# cyt6bj register map
Vendor: Cypress Semiconductor; Series: cyt6bj; File version: 1.0
CPU: CM7 r0p1, little endian, MPU, FPU, VTOR, 3 interrupt priority bits
Registers are 32-bit, read-write, reset 0x0 unless marked. A register's access mark holds for its fields unless they carry their own. Offsets are from the block's base; [hi:lo] are bit positions; {n}, {i} and the like mark numbered series; 'fields as' and 'values as' point back to an identical list; <NAME> marks a mode.

## CPUSS — CPU subsystem (CPUSS)
Base 0x40200000
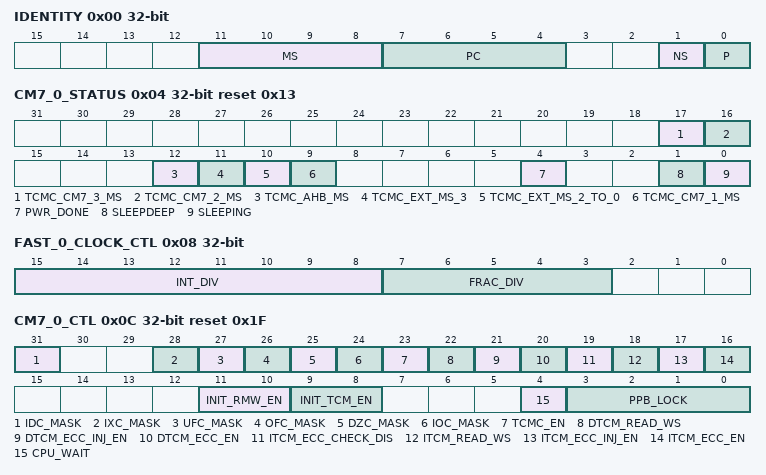
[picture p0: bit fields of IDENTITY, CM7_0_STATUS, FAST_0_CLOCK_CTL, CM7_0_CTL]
0x00 IDENTITY ro reset not defined
  [11:8] MS — This field specifies the bus master identifier of the transfer that reads the register.
  [7:4] PC — This field specifies the protection context of the transfer that reads the register.
  [1] NS — This field specifies the security setting ('0': secure mode; '1': non-secure mode) of the transfer that reads the register.
  [0] P — This field specifies the privileged setting ('0': user mode; '1': privileged mode) of the transfer that reads the register.
0x04 CM7_0_STATUS ro reset 0x13
  [17] TCMC_CM7_3_MS — Outstanding transactions from CM7 3. '0': There are no outstanding transactions to the CM7 I/D-TCM slave port (AHBS) from CM7 3. '1': There are outstanding transactions to the CM7 I/D-TCM slave port (AHBS) from CM7 3. Do not switch the CM7 power off.
  [16] TCMC_CM7_2_MS — Outstanding transactions from CM7 2. '0': There are no outstanding transactions to the CM7 I/D-TCM slave port (AHBS) from CM7 2. '1': There are outstanding transactions to the CM7 I/D-TCM slave port (AHBS) from CM7 2. Do not switch the CM7 power off.
  [12] TCMC_AHB_MS — Ongoing AHB transaction. '0': There is no ongoing transaction to the CM7 I/D-TCM slave port (AHBS) from an AHB master. '1': There is an ongoing transaction to the CM7 I/D-TCM slave port (AHBS) from an AHB master. Do not switch the CM7 power off.
  [11] TCMC_EXT_MS_3 — Outstanding transactions from external AXI master 3. '0': There are no outstanding transactions to the CM7 I/D-TCM slave port (AHBS) from external AXI master 3. '1': There are outstanding transactions to the CM7 I/D-TCM slave port (AHBS) from external AXI master 3. Do not switch the CM7 power off.
  [10] TCMC_EXT_MS_2_TO_0 — Outstanding transactions from external AXI masters 2 to 0. '0': There are no outstanding transactions to the CM7 I/D-TCM slave port (AHBS) from external AXI masters 2 to 0. '1': There are outstanding transactions to the CM7 I/D-TCM slave port (AHBS) from external AXI masters 2 to 0. Do not switch the CM7 power off.
  [9] TCMC_CM7_1_MS — Outstanding transactions from CM7 1. '0': There are no outstanding transactions to the CM7 I/D-TCM slave port (AHBS) from CM7 1. '1': There are outstanding transactions to the CM7 I/D-TCM slave port (AHBS) from CM7 1. Do not switch the CM7 power off.
  [4] PWR_DONE — After a PWR_MODE change this flag indicates if the new power mode has taken effect or not. Note: this flag can also change as a result of a change in debug power up req
  [1] SLEEPDEEP — Specifies if the CPU is in Sleep or DeepSleep power mode. See SLEEPING field.
  [0] SLEEPING — Specifies if the CPU is in Active, Sleep or DeepSleep power mode: - Active power mode: SLEEPING is '0'. - Sleep power mode: SLEEPING is '1' and SLEEPDEEP is '0'. - DeepSleep power mode: SLEEPING is '1' and SLEEPDEEP is '1'.
0x08 FAST_0_CLOCK_CTL — Fast 0 clock control
  [15:8] INT_DIV — Integer division by (1+INT_DIV). Allows for integer divisions in the range [1, 256] (INT_DIV is in the range [0, 255]).
  [7:3] FRAC_DIV — Fractional division by (FRAC_DIV/32). Allows for fractional divisions in the range [0, 31/32]. Note that fractional division results in clock jitter as some clock periods may be 1 'clk_hf<x>' cycle longer than other clock periods.
0x0C CM7_0_CTL reset 0x1F — CM7 0 control
  [31] IDC_MASK — CPU FPU exception mask for the CPU's FPCSR.IDC 'input denormalized' exception condition: '0': The CPU's exception condition does NOT activate the CPU's floating point interrupt. '1': the CPU's exception condition activates the CPU's floating point interrupt. Note: if the CPU FPCSR.FZ field is set to '1', denormalized inputs are 'flushed to zero'. Dependent on the FPU algorithm, this may or may not occur frequently. To prevent frequent CPU FPU interrupts as a result of denormalized inputs, this field may be set to '0'.
  [28] IXC_MASK — CPU FPU exception mask for the CPU's FPCSR.IXC 'inexact' exception condition: '0': The CPU's exception condition does NOT activate the CPU's floating point interrupt. '1': the CPU's exception condition activates the CPU's floating point interrupt. Note: the 'inexact' condition is set as a result of rounding. Rounding may occur frequently and is typically not an error condition. To prevent frequent CPU FPU interrupts as a result of rounding, this field is typically set to '0'.
  [27] UFC_MASK — CPU FPU exception mask for the CPU's FPCSR.UFC 'underflow' exception condition: '0': The CPU's exception condition does NOT activate the CPU's floating point interrupt. '1': the CPU's exception condition activates the CPU's floating point interrupt.
  [26] OFC_MASK — CPU FPU exception mask for the CPU's FPCSR.OFC 'overflow' exception condition: '0': The CPU's exception condition does NOT activate the CPU's floating point interrupt. '1': the CPU's exception condition activates the CPU's floating point interrupt.
  [25] DZC_MASK — CPU FPU exception mask for the CPU's FPCSR.DZC 'divide by zero' exception condition: '0': The CPU's exception condition does NOT activate the CPU's floating point interrupt. '1': the CPU's exception condition activates the CPU's floating point interrupt.
  [24] IOC_MASK — CPU floating point unit (FPU) exception mask for the CPU's FPCSR.IOC 'invalid operation' exception condition: '0': The CPU's exception condition does NOT activate the CPU's floating point interrupt. '1': the CPU's exception condition activates the CPU's floating point interrupt. Note: the ARM architecture does NOT support FPU exceptions; i.e. there is no precise FPU exception handler. Instead, FPU conditions are captured in the CPU's FPCSR register and the conditions are provided as CPU interface signals. The interface signals are 'masked' with the fields a provide by this register (CM7_0_CTL). The 'masked' signals are reduced/OR-ed into a single CPU floating point interrupt signal. The associated CPU interrupt handler allows for imprecise handling of FPU exception conditions. Note: the CPU's FPCSR exception conditions are 'sticky'. Typically, the CPU FPU interrupt handler will clear the exception condition(s) to '0'. Note: by default, the FPU exception masks are '0'. Therefore, FPU exception conditions will NOT activate the CPU's floating point interrupt.
  [23] TCMC_EN — CM7 TCMC access control: '0': Disable access to the CM7 I/D-TCM slave port (AHBS). Access attempts will get a bus error response. '1': Enable access to the CM7 I/D-TCM slave port (AHBS). Before switching the CM7 power off, set this field to 0, and confirm that there are no outstanding AXI transactions and no ongoing AHB transactions to the CM7 TCMs, by checking that bits TCMC_* in CM7_x_STATUS are '0'.
  [22] DTCM_READ_WS — DTCM read wait states (writes have no wait states). '0': 0 wait states. '1': 1 wait state.
  [21] DTCM_ECC_INJ_EN — DTCM ECC error injection enable: '0': Disabled. '1': Enabled.
  [20] DTCM_ECC_EN — DTCM ECC enable: '0': Disabled. '1': Enabled.
  [19] ITCM_ECC_CHECK_DIS — Disable ECC checking and thus fault reports. This also disables ECC correction (required to enable initialization). Intended usage is initialization. This bit is ignored when TCM_ECC_EN=0.
  [18] ITCM_READ_WS — ITCM read wait states (writes have no wait states). '0': 0 wait states. '1': 1 wait state.
  [17] ITCM_ECC_INJ_EN — ITCM ECC error injection enable: '0': Disabled. '1': Enabled.
  [16] ITCM_ECC_EN — ITCM ECC enable: '0': Disabled. '1': Enabled.
  [11:10] INIT_RMW_EN — TCM read-modify-write enable initialization after reset: Bit 0: ITCM. '0': disabled; '1': enabled. Bit 1: DTCM. '0': disabled; '1': enabled. Note: When TCM ECC is enabled, the read-modify-write functionality should be enabled. This prevents partial (sub-word) writes to the TCM.
  [9:8] INIT_TCM_EN — TCM enable initialization after reset: Bit 0: ITCM. '0': disabled; '1': enabled. Bit 1: DTCM. '0': disabled; '1': enabled.
  [4] CPU_WAIT — When this signal is '1' out of reset, it forces the CPU into a quiescent state that delays its boot-up sequence and instruction execution until this signal is driven '0'. This allows the TCMs to be loaded by the system before the CPU performs any TCM accesses. The CPU AHBS interface functions while CPU_WAIT is '1' and services transactions initiated by the system (e.g. DMA controller) to load the TCMs.
  [3:0] PPB_LOCK — Write disable for specific CPU registers: Bit 0: ITCMR register. '0': enabled; '1': disabled. Bit 1: DTCMR register. '0': enabled; '1': disabled. Bit 2: AHBPCR register. '0': enabled; '1': disabled. Bit 3: VTOR register. '0': enabled; '1': disabled.
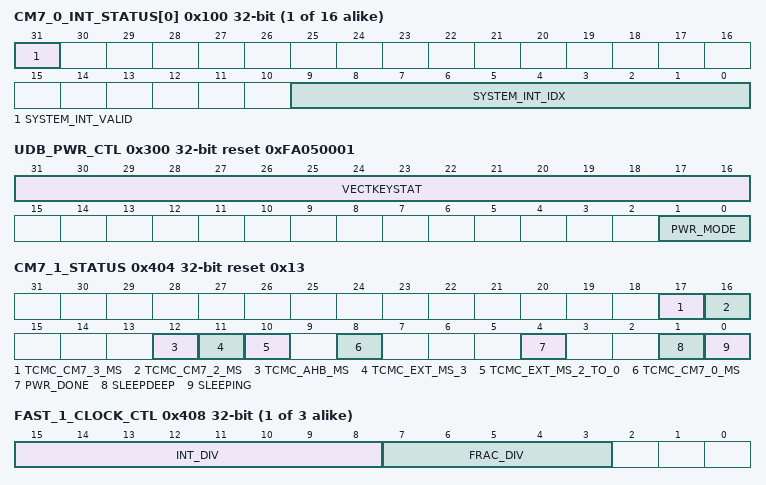
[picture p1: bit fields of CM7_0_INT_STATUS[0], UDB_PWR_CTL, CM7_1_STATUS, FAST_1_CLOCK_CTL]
{0x100+4i} CM7_0_INT_STATUS[{i}] (i=0..15) ro (reset mask 0x80000000) — CM7 0 interrupt status
  [31] SYSTEM_INT_VALID — See description of CM0_INT0_STATUS.
  [9:0] SYSTEM_INT_IDX — Lowest CM7_0 activated system interrupt index for CPU interrupt. See description of CM0_INT0_STATUS.
{0x200+0x400*i} CM7_{i}_VECTOR_TABLE_BASE reset 0x1000000 (i=0..3)
  [31:7] ADDR25 — The default CM7 vector table base address is 0x0100:0000 (CM7 VTOR and reset exception handler address after reset). This is the location of the system ROM memory. The system ROM is mirrored at 0x0000:0000. This is required for the CM0+ boot process (the CM0+ VTOR and reset exception handler address is at fixed address 0x0000:00000 after reset). The system ROM requires mirroring as the CM7 CPUs' ITCMs are located at base address 0x0000:0000 and effectively cut a hole in the system ROM mirror address space (but the 0x0100:0000 address space is not affected).
{0x240+4i} CM7_0_NMI_CTL[{i}] (i=0..3) reset 0x3FF — CM7 0 NMI control
  [9:0] SYSTEM_INT_IDX — System interrupt select for CPU NMI. The reset value ('1023') ensures that the CPU NMI is NOT connected to any system interrupt after DeepSleep reset.
0x300 UDB_PWR_CTL reset 0xFA050001 — UDB power control
  [31:16] VECTKEYSTAT ro — Register key (to prevent accidental writes). - Should be written with a 0x05fa key value for the write to take effect. - Always reads as 0xfa05.
  [1:0] PWR_MODE — Set Power mode for UDBs
    0=OFF (See CM7_0_PWR_CTL); 1=RESET (See CM7_0_PWR_CTL); 2=RETAINED (See CM7_0_PWR_CTL); 3=ENABLED (See CM7_0_PWR_CTL)
0x304 UDB_PWR_DELAY_CTL reset 0x12C — UDB power control
  [9:0] UP — Number clock cycles delay needed after power domain power up
0x320 TRC_DBG_CLOCK_CTL reset 0x200 — Trace and debug clock control
  [15:8] INT_DIV — Integer division by (1+INT_DIV). Allows for integer divisions in the range [1, 256] (INT_DIV is in the range [0, 255]). Note that this field is retained. However, the counter that is used to implement the division is not and will be initialized by HW to '0' when transitioning from DeepSleep to Active power mode.
0x404 CM7_1_STATUS ro reset 0x13
  [17] TCMC_CM7_3_MS — Outstanding transactions from CM7 3. '0': There are no outstanding transactions to the CM7 I/D-TCM slave port (AHBS) from CM7 3. '1': There are outstanding transactions to the CM7 I/D-TCM slave port (AHBS) from CM7 3. Do not switch the CM7 power off.
  [16] TCMC_CM7_2_MS — Outstanding transactions from CM7 2. '0': There are no outstanding transactions to the CM7 I/D-TCM slave port (AHBS) from CM7 2. '1': There are outstanding transactions to the CM7 I/D-TCM slave port (AHBS) from CM7 2. Do not switch the CM7 power off.
  [12] TCMC_AHB_MS — Refer CM7_0_STATUS description.
  [11] TCMC_EXT_MS_3 — Refer CM7_0_STATUS description.
  [10] TCMC_EXT_MS_2_TO_0 — Refer CM7_0_STATUS description.
  [8] TCMC_CM7_0_MS — Outstanding transactions from CM7 0. '0': There are no outstanding transactions to the CM7 I/D-TCM slave port (AHBS) from CM7 0. '1': There are outstanding transactions to the CM7 I/D-TCM slave port (AHBS) from CM7 0. Do not switch the CM7 power off.
  [4] PWR_DONE — After a PWR_MODE change this flag indicates if the new power mode has taken effect or not. Note: this flag can also change as a result of a change in debug power up req
  [1] SLEEPDEEP — Specifies if the CPU is in Sleep or DeepSleep power mode. See SLEEPING field.
  [0] SLEEPING — Specifies if the CPU is in Active, Sleep or DeepSleep power mode: - Active power mode: SLEEPING is '0'. - Sleep power mode: SLEEPING is '1' and SLEEPDEEP is '0'. - DeepSleep power mode: SLEEPING is '1' and SLEEPDEEP is '1'.
{0x8+0x400*i} FAST_{i}_CLOCK_CTL (i=1..3) — Fast {i} clock control
  [15:8] INT_DIV — Refer FAST_0_CLOCK_CTL description.
  [7:3] FRAC_DIV — Refer FAST_0_CLOCK_CTL description.
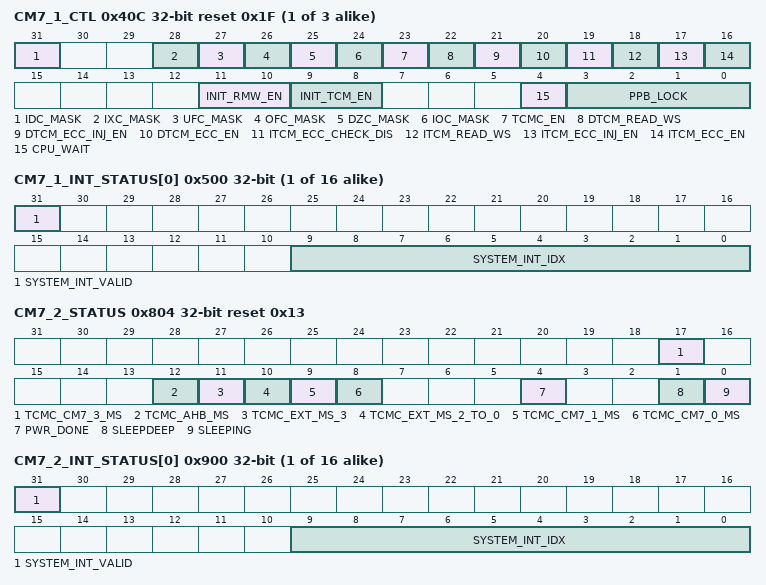
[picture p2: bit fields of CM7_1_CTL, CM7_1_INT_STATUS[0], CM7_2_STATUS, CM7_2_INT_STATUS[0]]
{0xC+0x400*i} CM7_{i}_CTL reset 0x1F (i=1..3) — CM7 {i} control
  [31] IDC_MASK — Refer CM7_0_CTL description.
  [28] IXC_MASK — Refer CM7_0_CTL description.
  [27] UFC_MASK — Refer CM7_0_CTL description.
  [26] OFC_MASK — Refer CM7_0_CTL description.
  [25] DZC_MASK — Refer CM7_0_CTL description.
  [24] IOC_MASK — Refer CM7_0_CTL description.
  [23] TCMC_EN — Refer CM7_0_CTL description.
  [22] DTCM_READ_WS — Refer CM7_0_CTL description.
  [21] DTCM_ECC_INJ_EN — Refer CM7_0_CTL description.
  [20] DTCM_ECC_EN — Refer CM7_0_CTL description.
  [19] ITCM_ECC_CHECK_DIS — Disable ECC checking and thus fault reports. This also disables ECC correction (required to enable initialization). Intended usage is initialization. This bit is ignored when TCM_ECC_EN=0.
  [18] ITCM_READ_WS — Refer CM7_0_CTL description.
  [17] ITCM_ECC_INJ_EN — Refer CM7_0_CTL description.
  [16] ITCM_ECC_EN — Refer CM7_0_CTL description.
  [11:10] INIT_RMW_EN — Refer CM7_0_CTL description.
  [9:8] INIT_TCM_EN — Refer CM7_0_CTL description.
  [4] CPU_WAIT — Refer CM7_0_CTL description.
  [3:0] PPB_LOCK — Refer CM7_0_CTL description.
{0x500+4i} CM7_1_INT_STATUS[{i}] (i=0..15) ro (reset mask 0x80000000) — CM7 1 interrupt status
  [31] SYSTEM_INT_VALID — See description of CM0_INT0_STATUS.
  [9:0] SYSTEM_INT_IDX — Lowest CM7_1 activated system interrupt index for CPU interrupt 0. See description of CM0_INT0_STATUS.
{0x640+4i} CM7_1_NMI_CTL[{i}] (i=0..3) reset 0x3FF — CM7 1 NMI control
  [9:0] SYSTEM_INT_IDX — Refer CM7_0_NMI_CTL description.
0x804 CM7_2_STATUS ro reset 0x13
  [17] TCMC_CM7_3_MS — Outstanding transactions from CM7 3. '0': There are no outstanding transactions to the CM7 I/D-TCM slave port (AHBS) from CM7 3. '1': There are outstanding transactions to the CM7 I/D-TCM slave port (AHBS) from CM7 3. Do not switch the CM7 power off.
  [12] TCMC_AHB_MS — Refer CM7_0_STATUS description.
  [11] TCMC_EXT_MS_3 — Refer CM7_0_STATUS description.
  [10] TCMC_EXT_MS_2_TO_0 — Refer CM7_0_STATUS description.
  [9] TCMC_CM7_1_MS — Outstanding transactions from CM7 1. '0': There are no outstanding transactions to the CM7 I/D-TCM slave port (AHBS) from CM7 1. '1': There are outstanding transactions to the CM7 I/D-TCM slave port (AHBS) from CM7 1. Do not switch the CM7 power off.
  [8] TCMC_CM7_0_MS — Outstanding transactions from CM7 0. '0': There are no outstanding transactions to the CM7 I/D-TCM slave port (AHBS) from CM7 0. '1': There are outstanding transactions to the CM7 I/D-TCM slave port (AHBS) from CM7 0. Do not switch the CM7 power off.
  [4] PWR_DONE — After a PWR_MODE change this flag indicates if the new power mode has taken effect or not. Note: this flag can also change as a result of a change in debug power up req
  [1] SLEEPDEEP — Specifies if the CPU is in Sleep or DeepSleep power mode. See SLEEPING field.
  [0] SLEEPING — Specifies if the CPU is in Active, Sleep or DeepSleep power mode: - Active power mode: SLEEPING is '0'. - Sleep power mode: SLEEPING is '1' and SLEEPDEEP is '0'. - DeepSleep power mode: SLEEPING is '1' and SLEEPDEEP is '1'.
{0x900+4i} CM7_2_INT_STATUS[{i}] (i=0..15) ro (reset mask 0x80000000) — CM7 2 interrupt status
  [31] SYSTEM_INT_VALID — See description of CM0_INT0_STATUS.
  [9:0] SYSTEM_INT_IDX — Lowest CM7_2 activated system interrupt index for CPU interrupt 0. See description of CM0_INT0_STATUS.
{0xA40+4i} CM7_2_NMI_CTL[{i}] (i=0..3) reset 0x3FF — CM7 2 NMI control
  [9:0] SYSTEM_INT_IDX — Refer CM7_0_NMI_CTL description.
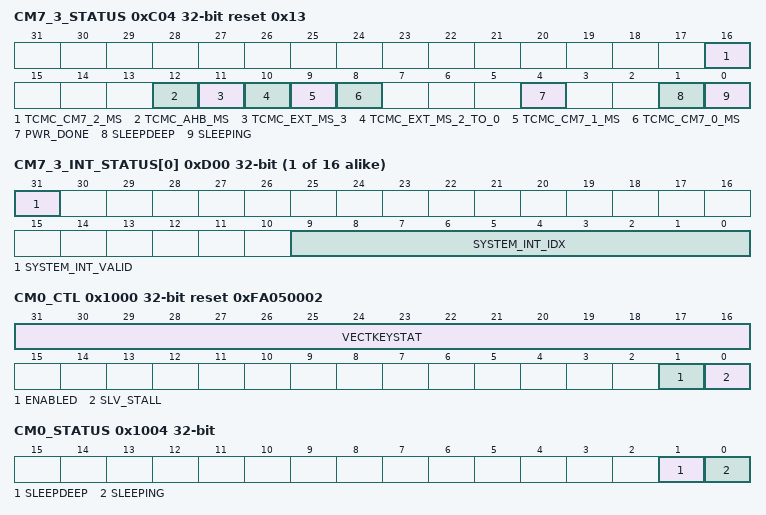
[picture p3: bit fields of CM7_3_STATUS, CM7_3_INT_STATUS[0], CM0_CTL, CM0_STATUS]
0xC04 CM7_3_STATUS ro reset 0x13
  [16] TCMC_CM7_2_MS — Outstanding transactions from CM7 2. '0': There are no outstanding transactions to the CM7 I/D-TCM slave port (AHBS) from CM7 2. '1': There are outstanding transactions to the CM7 I/D-TCM slave port (AHBS) from CM7 2. Do not switch the CM7 power off.
  [12] TCMC_AHB_MS — Refer CM7_0_STATUS description.
  [11] TCMC_EXT_MS_3 — Refer CM7_0_STATUS description.
  [10] TCMC_EXT_MS_2_TO_0 — Refer CM7_0_STATUS description.
  [9] TCMC_CM7_1_MS — Outstanding transactions from CM7 1. '0': There are no outstanding transactions to the CM7 I/D-TCM slave port (AHBS) from CM7 1. '1': There are outstanding transactions to the CM7 I/D-TCM slave port (AHBS) from CM7 1. Do not switch the CM7 power off.
  [8] TCMC_CM7_0_MS — Outstanding transactions from CM7 0. '0': There are no outstanding transactions to the CM7 I/D-TCM slave port (AHBS) from CM7 0. '1': There are outstanding transactions to the CM7 I/D-TCM slave port (AHBS) from CM7 0. Do not switch the CM7 power off.
  [4] PWR_DONE — After a PWR_MODE change this flag indicates if the new power mode has taken effect or not. Note: this flag can also change as a result of a change in debug power up req
  [1] SLEEPDEEP — Specifies if the CPU is in Sleep or DeepSleep power mode. See SLEEPING field.
  [0] SLEEPING — Specifies if the CPU is in Active, Sleep or DeepSleep power mode: - Active power mode: SLEEPING is '0'. - Sleep power mode: SLEEPING is '1' and SLEEPDEEP is '0'. - DeepSleep power mode: SLEEPING is '1' and SLEEPDEEP is '1'.
{0xD00+4i} CM7_3_INT_STATUS[{i}] (i=0..15) ro (reset mask 0x80000000) — CM7 3 interrupt status
  [31] SYSTEM_INT_VALID — See description of CM0_INT0_STATUS.
  [9:0] SYSTEM_INT_IDX — Lowest CM7_3 activated system interrupt index for CPU interrupt 0. See description of CM0_INT0_STATUS.
{0xE40+4i} CM7_3_NMI_CTL[{i}] (i=0..3) reset 0x3FF — CM7 3 NMI control
  [9:0] SYSTEM_INT_IDX — Refer CM7_0_NMI_CTL description.
0x1000 CM0_CTL reset 0xFA050002 — CM0+ control
  [31:16] VECTKEYSTAT ro — Register key (to prevent accidental writes). - Should be written with a 0x05fa key value for the write to take effect. - Always reads as 0xfa05. Note: Although the SW attribute for this field says ''R', SW need to write the key 0x05fa in this field for this register write to happen. This is a built in protection provided to prevent accidental writes from SW.
  [1] ENABLED — Processor enable: '0': Disabled. Processor clock is turned off and reset is activated. After SW clears this field to '0', HW automatically sets this field to '1'. This effectively results in a CM0+ reset, followed by a CM0+ warm boot. '1': Enabled. Note: The intent is that this bit is modified only through an external probe or by the CM7 while the CM0+ is in Sleep or DeepSleep power mode. If this field is cleared to '0' by the CM0+ itself, it should be done under controlled conditions (such that undesirable side effects can be prevented). Note: The CM0+ CPU has a AIRCR.SYSRESETREQ register field that allows the CM0+ to reset the complete device (ENABLED only disables/enables the CM0+), resulting in a warm boot. This CPU register field has similar 'built-in protection' as this CM0_CTL register to prevent accidental system writes (the upper 16-bits of the register need to be written with a 0x05fa key value; see CPU user manual for more details).
  [0] SLV_STALL — Processor debug access control: '0': Access. '1': Stall access. This field is used to stall/delay debug accesses. This is useful to protect execution of code that needs to be protected from debug accesses.
0x1004 CM0_STATUS ro
  [1] SLEEPDEEP — Specifies if the CPU is in Sleep or DeepSleep power mode. See SLEEPING field.
  [0] SLEEPING — Specifies if the CPU is in Active, Sleep or DeepSleep power mode: - Active power mode: SLEEPING is '0'. - Sleep power mode: SLEEPING is '1' and SLEEPDEEP is '0'. - DeepSleep power mode: SLEEPING is '1' and SLEEPDEEP is '1'.
0x1008 SLOW_CLOCK_CTL — Slow clock control
  [15:8] INT_DIV — Specifies the slow clock divider (from the memory/AXI clock 'clk_mem' to the slow clock 'clk_slow'). Integer division by (1+INT_DIV). Allows for integer divisions in the range [1, 256] (INT_DIV is in the range [0, 255]). Note that this field is retained. However, the counter that is used to implement the division is not and will be initialized by HW to '0' when transitioning from DeepSleep to Active power mode.
0x100C PERI_CLOCK_CTL — Peripheral interconnect clock control
  fields as TRC_DBG_CLOCK_CTL
0x1010 MEM_CLOCK_CTL — Memory clock control
  fields as TRC_DBG_CLOCK_CTL
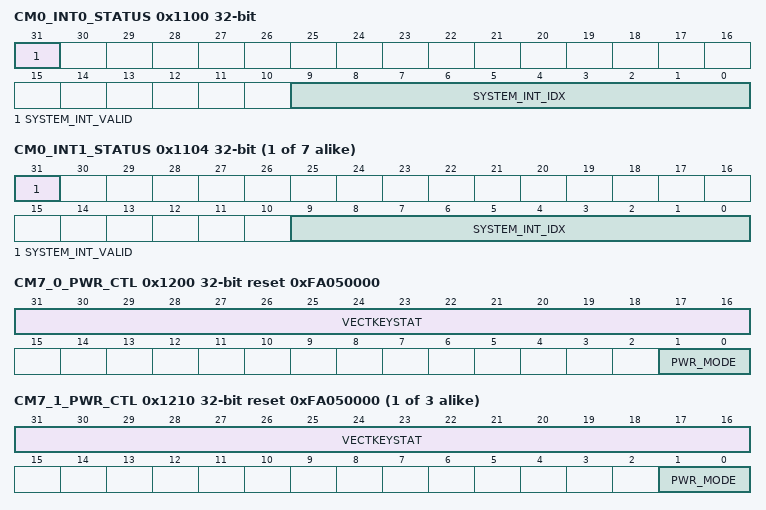
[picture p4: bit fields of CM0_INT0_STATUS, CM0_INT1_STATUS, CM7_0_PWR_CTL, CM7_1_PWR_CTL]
0x1100 CM0_INT0_STATUS ro (reset mask 0x80000000) — CM0+ interrupt 0 status
  [31] SYSTEM_INT_VALID — Valid indication for SYSTEM_INT_IDX. When '0', no system interrupt for CPU interrupt 0 is valid/activated.
  [9:0] SYSTEM_INT_IDX — Lowest CM0+ activated system interrupt index for CPU interrupt 0. Multiple system interrupts can be mapped on the same CPU interrupt.The selected system interrupt is the system interrupt with the lowest system interrupt index that has an activated interrupt request at the time of the fetch (system_interrupts[SYSTEM_INT_IDX] is '1'). The CPU interrupt handler SW can read SYSTEM_INT_IDX to determine the system interrupt that activated the handler.
{0x1100+4i} CM0_INT{i}_STATUS ro (reset mask 0x80000000) (i=1..7) — CM0+ interrupt {i} status
  [31] SYSTEM_INT_VALID — See description of CM0_INT0_STATUS.
  [9:0] SYSTEM_INT_IDX — Lowest CM0+ activated system interrupt index for CPU interrupt {i}. See description of CM0_INT0_STATUS.
0x1120 CM0_VECTOR_TABLE_BASE
  [31:8] ADDR24 — The default CM0+ vector table base address is 0x0000:0000 (CM0+ VTOR and reset exception handler address after reset). This is the location of the mirror system ROM memory. This register is provided for SW purposes. It 'survives' a CM0+ warm reset cycle (CM0_CTL.ENABLED). Note: the use of the mirror system ROM memory can be disabled using the protection infrastructure (SMPU).
{0x1140+4i} CM0_NMI_CTL[{i}] (i=0..3) reset 0x3FF — CM0+ NMI control
  fields as CM7_0_NMI_CTL[0]
0x1200 CM7_0_PWR_CTL reset 0xFA050000 — CM7 0 power control
  [31:16] VECTKEYSTAT ro — Register key (to prevent accidental writes). - Should be written with a 0x05fa key value for the write to take effect. - Always reads as 0xfa05. Note: Although the SW attribute for this field says ''R', SW need to write the key 0x05fa in this field for this register write to happen. This is a built in protection provided to prevent accidental writes from SW.
  [1:0] PWR_MODE — Power mode.
    0=OFF (Switch CM7_0 off Power off, clock off, isolate, reset and no retain.); 1=RESET (Reset CM7_0 Clock off, no isolated, no retain and reset. Note: The CM7_0 CPU has a AIRCR.SYSRESETREQ register field that allows the CM7_0 to reset the complete device (RESET only resets the CM7_0), resulting in a warm boot.); 2=RETAINED (Put CM7_0 in Retained mode This can only become effective if CM7_0 is in SleepDeep mode. Check PWR_DONE flag to see if CM7_0 RETAINED state has been reached. Power off, clock off, isolate, no reset and retain.); 3=ENABLED (Switch CM7_0 on. Power on, clock on, no isolate, no reset and no retain.)
{0x1204+0x10*i} CM7_{i}_PWR_DELAY_CTL reset 0x12C (i=0..3) — CM7 {i} power delay control
  fields as UDB_PWR_DELAY_CTL
{0x1200+0x10*i} CM7_{i}_PWR_CTL reset 0xFA050000 (i=1..3) — CM7 {i} power control
  [31:16] VECTKEYSTAT ro — Refer CM7_0_PWR_CTL description.
  [1:0] PWR_MODE — Refer CM7_0_PWR_CTL description.
    0=OFF (Refer CM7_0_PWR_CTL description.); 1=RESET (Refer CM7_0_PWR_CTL description.); 2=RETAINED (Refer CM7_0_PWR_CTL description.); 3=ENABLED (Refer CM7_0_PWR_CTL description.)
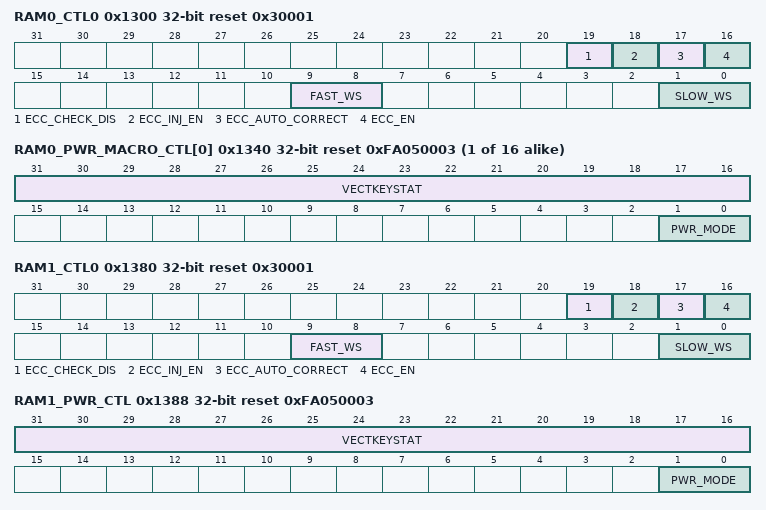
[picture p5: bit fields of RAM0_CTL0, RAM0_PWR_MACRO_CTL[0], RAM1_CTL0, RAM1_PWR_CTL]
0x1300 RAM0_CTL0 reset 0x30001 — RAM 0 control
  [19] ECC_CHECK_DIS — Disable ECC checking and thus fault reports. This also disables ECC correction (required to enable initialization). Intended usage is initialization. This bit is ignored when ECC_EN=0.
  [18] ECC_INJ_EN — Enable ECC parity injection. Instead of calculating the parity from the write data to the RAM, the parity is taken from ECC_CTL PARITY upon a match of ECC_CTL WORD_ADDR. The write data can be of any size. This bit is ignored when ECC_EN=0. Note: Parity injection invalidates the write buffer for this word address. If only a part of 64-bit data is written and consistency should be maintained, RAMC#_STATUS WB_EMPTY=1 should be checked before.
  [17] ECC_AUTO_CORRECT — HW ECC autocorrect functionality: '0': Disabled. '1': Enabled. HW automatically writes back SRAM with corrected data when a recoverable ECC error is detected.
  [16] ECC_EN — Enable ECC checking: '0': Disabled. '1': Enabled.
  [9:8] FAST_WS — Memory wait states for the fast clock domain ('clk_fast_0/1') interface. The number of wait states is expressed in 'clk_mem' clock domain cycles.
  [1:0] SLOW_WS — Memory wait states for the slow clock domain ('clk_slow') intefrace. The number of wait states is expressed in 'clk_mem' clock domain cycles.
0x1304 RAM0_STATUS ro reset 0x1
  [0] WB_EMPTY — Write buffer empty. This information is used when entering DeepSleep power mode: WB_EMPTY must be '1' before a transition to system DeepSleep power mode. '0': Write buffer NOT empty. '1': Write buffer empty. Note: the SRAM controller write buffer is only used when ECC checking is enabled. (RAMi_CTL.ECC_EN is '1').
{0x1340+4i} RAM0_PWR_MACRO_CTL[{i}] (i=0..15) reset 0xFA050003 — RAM 0 power control
  [31:16] VECTKEYSTAT ro — Register key (to prevent accidental writes). - Should be written with a 0x05fa key value for the write to take effect. - Always reads as 0xfa05. Note: Although the SW attribute for this field says ''R', SW need to write the key 0x05fa in this field for this register write to happen. This is a built in protection provided to prevent accidental writes from SW.
  [1:0] PWR_MODE — Power mode.
    0=OFF (Turn OFF the SRAM. This will trun OFF both array and periphery power of the SRAM and SRAM memory contents are lost.); 1=RSVD (undefined); 2=RETAINED (Keep SRAM in Retained mode. This will turn OFF the SRAM periphery power, but array power is ON to retain memory contents.); 3=ENABLED (Enable SRAM for regular operation.)
0x1380 RAM1_CTL0 reset 0x30001 — RAM 1 control
  [19] ECC_CHECK_DIS — Disable ECC checking and thus fault reports. This also disables ECC correction (required to enable initialization). Intended usage is initialization. This bit is ignored when ECC_EN=0.
  [18] ECC_INJ_EN — Enable ECC parity injection. Instead of calculating the parity from the write data to the RAM, the parity is taken from ECC_CTL PARITY upon a match of ECC_CTL WORD_ADDR. The write data can be of any size. This bit is ignored when ECC_EN=0. Note: Parity injection invalidates the write buffer for this word address. If only a part of 64-bit data is written and consistency should be maintained, RAMC#_STATUS WB_EMPTY=1 should be checked before.
  [17] ECC_AUTO_CORRECT — Refer RAM0_CTL0 descriotion.
  [16] ECC_EN — Refer RAM0_CTL0 descriotion.
  [9:8] FAST_WS — Refer RAM0_CTL0 descriotion.
  [1:0] SLOW_WS — Refer RAM0_CTL0 descriotion.
0x1384 RAM1_STATUS ro reset 0x1
  [0] WB_EMPTY — Refer RAM0_STATUS description.
0x1388 RAM1_PWR_CTL reset 0xFA050003 — RAM 1 power control
  [31:16] VECTKEYSTAT ro — Refer RAM0_PWR_MACRO_CTL description.
  [1:0] PWR_MODE — Power mode.
    0=OFF (Refer RAM0_PWR_MACRO_CTL description.); 1=RSVD (Undefined.); 2=RETAINED (Refer RAM0_PWR_MACRO_CTL description.); 3=ENABLED (Refer RAM0_PWR_MACRO_CTL description.)
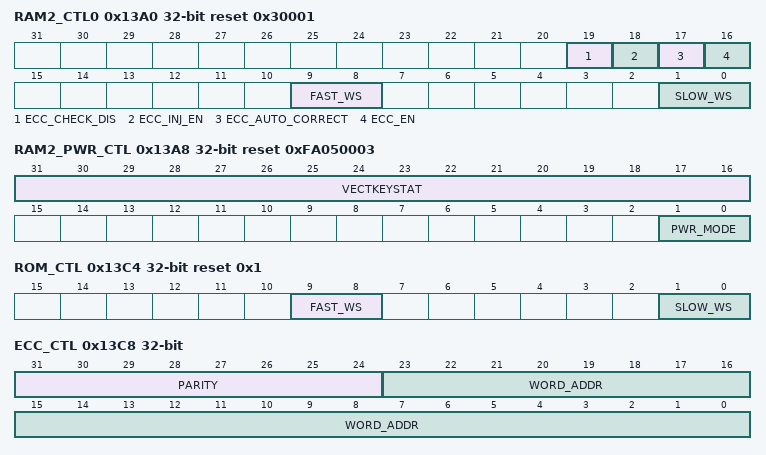
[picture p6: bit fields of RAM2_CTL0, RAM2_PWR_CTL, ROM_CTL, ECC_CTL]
0x13A0 RAM2_CTL0 reset 0x30001 — RAM 2 control
  fields as RAM1_CTL0
0x13A4 RAM2_STATUS ro reset 0x1
  [0] WB_EMPTY — Refer RAM0_STATUS description.
0x13A8 RAM2_PWR_CTL reset 0xFA050003 — RAM 2 power control
  fields as RAM1_PWR_CTL
0x13C0 RAM_PWR_DELAY_CTL reset 0x96 — Power up delay used for all SRAM power domains
  fields as UDB_PWR_DELAY_CTL
0x13C4 ROM_CTL reset 0x1 — ROM control
  [9:8] FAST_WS — Memory wait states for the fast clock domain ('clk_fast'). The number of wait states is expressed in 'clk_mem' clock domain cycles. ROM_CTL.FAST_WS = '0' when clk_mem <= 200MHz.
  [1:0] SLOW_WS — Memory wait states for the slow clock domain ('clk_slow'). The number of wait states is expressed in 'clk_mem' clock domain cycles. Timing paths to and from the memory have a (fixed) minimum duration that always needs to be considered/met. The 'clk_mem' clock domain frequency determines this field's value such that the timing paths minimum duration is met. ROM_CTL.SLOW_WS = '0' when clk_mem <=100 MHz. ROM_CTL.SLOW_WS = '1' when 100MHz < clk_mem <=200MHz.
0x13C8 ECC_CTL — ECC control
  [31:24] PARITY — ECC parity to use for ECC error injection at address WORD_ADDR. For the DTCM which has only 7 parity bits, PARITY[6:0] is used as ECC parity.
  [23:0] WORD_ADDR — Specifies the word address where an error will be injected. - On a write transfer to this SRAM address and when the corresponding RAM0/RAM1/RAM2/ITCM/DTCM ECC_INJ_EN bit is '1', the parity (PARITY) is injected. This field needs to be written with the offset address within the memory, divided by the ECC word width in bytes (for RAM0/RAM1/RAM2/ITCM this is 8, for DTCM this is 4). For example, if the RAM0 start address is 0x2800000, and an error is to be injected to address 0x28000080, then this field needs to configured to 0x000010.
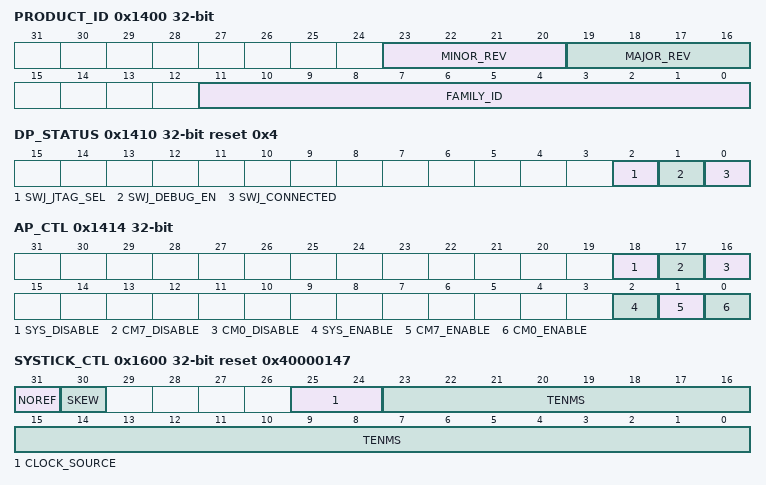
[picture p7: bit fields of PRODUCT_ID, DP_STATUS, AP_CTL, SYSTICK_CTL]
0x1400 PRODUCT_ID ro (reset mask 0xFFF) — Product identifier and version (same as CoreSight RomTables)
  [23:20] MINOR_REV — Minir Revision, starts with 1, increments with metal layer only tape-out (implemented with metal ECO-able tie-off)
  [19:16] MAJOR_REV — Major Revision, starts with 1, increments with all layer tape-out (implemented with metal ECO-able tie-off)
  [11:0] FAMILY_ID — Family ID. Common ID for a product family.
0x1410 DP_STATUS ro reset 0x4 — Debug port status
  [2] SWJ_JTAG_SEL — Specifies if the JTAG or SWD interface is selected. This signal is valid when DP_CTL.PTM_SEL is '0' (SWJ mode selected) and SWJ_CONNECTED is '1' (SWJ is connected). '0': SWD selected. '1': JTAG selected.
  [1] SWJ_DEBUG_EN — Specifies if SWJ debug is enabled, i.e. CDBGPWRUPACK is '1' and thus debug clocks are on: '0': Disabled. '1': Enabled.
  [0] SWJ_CONNECTED — Specifies if the SWJ debug port is connected; i.e. debug host interface is active: '0': Not connected/not active. '1': Connected/active.
0x1414 AP_CTL — Access port control
  [18] SYS_DISABLE — Disables the system AP interface: '0': Enabled. '1': Disabled. Typically, this field is set by the Cypress boot code with information from eFUSE. The access port is only enabled when SYS_DISABLE is '0' and SYS_ENABLE is '1'.
  [17] CM7_DISABLE — Disables the CM7_0 and CM7_1 and CM7_2 and CM7_3 AP interface: '0': Enabled. '1': Disabled. Typically, this field is set by the Cypress boot code with information from eFUSE. The access port is only enabled when CM7_DISABLE is '0' and CM7_ENABLE is '1'.
  [16] CM0_DISABLE — Disables the CM0 AP interface: '0': Enabled. '1': Disabled. Typically, this field is set by the Cypress boot code with information from eFUSE. The access port is only enabled when CM0_DISABLE is '0' and CM0_ENABLE is '1'.
  [2] SYS_ENABLE — Enables the system AP interface: '0': Disabled. '1': Enabled.
  [1] CM7_ENABLE — Enables the CM7_0 and CM7_1 and CM7_2 and CM7_3 AP interface: '0': Disabled. '1': Enabled.
  [0] CM0_ENABLE — Enables the CM0 AP interface: '0': Disabled. '1': Enabled.
0x1500 BUFF_CTL reset 0x1 — Buffer control
  [0] WRITE_BUFF — Specifies if write transfer can be buffered in the bus infrastructure bridges: '0': Write transfers are not buffered, independent of the transfer's bufferable attribute. '1': Write transfers can be buffered, if the transfer's bufferable attribute indicates that the transfer is a bufferable/posted write.
0x1600 SYSTICK_CTL reset 0x40000147 — SysTick timer control
  [31] NOREF — Specifies if an external clock source is provided: '0': An external clock source is provided. '1': An external clock source is NOT provided and only the CPU internal clock can be used as SysTick timer clock source.
  [30] SKEW — Specifies the precision of the clock source and if the TENMS field represents exactly 10 ms (clock source frequency is a multiple of 100 Hz). This affects the suitability of the SysTick timer as a SW real-time clock: '0': Precise. '1': Imprecise.
  [25:24] CLOCK_SOURCE — Specifies an external clock source: '0': The low frequency clock 'clk_lf' is selected. The precision of this clock depends on whether the low frequency clock source is a SRSS internal RC oscillator (imprecise) or a device external crystal oscillator (precise). '1': The internal main oscillator (IMO) clock 'clk_imo' is selected. The MXS40 platform uses a fixed frequency IMO clock. o '2': The external crystal oscillator (ECO) clock 'clk_eco' is selected. '3': The SRSS 'clk_timer' is selected ('clk_timer' is a divided/gated version of 'clk_hf' or 'clk_imo'). Note: If NOREF is '1', the CLOCK_SOURCE value is NOT used. Note: It is SW's responsibility to provide the correct NOREF, SKEW and TENMS field values for the selected clock source.
  [23:0] TENMS — Specifies the number of clock source cycles (minus 1) that make up 10 ms. E.g., for a 32,768 Hz reference clock, TENMS is 328 - 1 = 327.
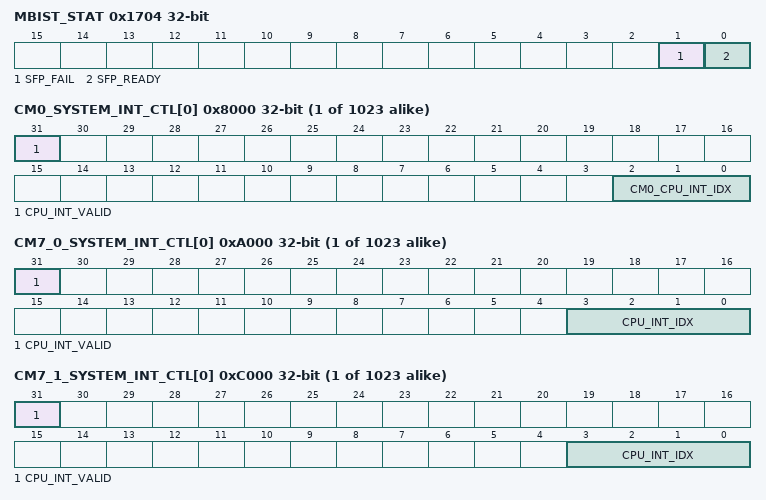
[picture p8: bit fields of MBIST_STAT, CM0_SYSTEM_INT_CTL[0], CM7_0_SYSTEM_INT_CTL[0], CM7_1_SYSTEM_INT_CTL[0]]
0x1704 MBIST_STAT ro — Memory BIST status
  [1] SFP_FAIL — Report status of the BIST run, only valid if SFP_READY=1
  [0] SFP_READY — Flag indicating the BIST run is done. Note that after starting a BIST run this flag must be set before a new run can be started. For the first BIST run this will be 0.
0x1800 CAL_SUP_SET — Calibration support set and read
  [31:0] DATA — Read without side effect, write 1 to set
0x1804 CAL_SUP_CLR — Calibration support clear and reset
  [31:0] DATA — Read side effect: when read all bits are cleared, write 1 to clear a specific bit Note: no exception for the debug host, it also causes the read side effect
0x2000 CM0_PC_CTL — CM0+ protection context control
  [3:0] VALID — Valid fields for the protection context handler CM0_PCi_HANDLER registers: Bit 0: Valid field for CM0_PC0_HANDLER. Bit 1: Valid field for CM0_PC1_HANDLER. Bit 2: Valid field for CM0_PC2_HANDLER. Bit 3: Valid field for CM0_PC3_HANDLER.
0x2040 CM0_PC0_HANDLER — CM0+ protection context 0 handler
  [31:0] ADDR — Address of the protection context 0 handler. This field is used to detect entry to Cypress 'trusted' code through an exception/interrupt.
{0x2040+4i} CM0_PC{i}_HANDLER (i=1..3) — CM0+ protection context {i} handler
  [31:0] ADDR — Address of the protection context {i} handler.
0x20C4 PROTECTION — Protection status
  [2:0] STATE — Protection state: '0': UNKNOWN. '1': VIRGIN. '2': NORMAL. '3': SECURE. '4': DEAD. The following state transistions are allowed (and enforced by HW): - UNKNOWN => VIRGIN/NORMAL/SECURE/DEAD - NORMAL => DEAD - SECURE => DEAD An attempt to make a NOT allowed state transition will NOT affect this register field.
    0=UNKNOWN (N/A); 1=VIRGIN (N/A); 2=NORMAL (N/A); 3=SECURE (N/A); 4=DEAD (N/A)
0x2100 TRIM_ROM_CTL — ROM trim control
  [31:0] TRIM
0x2104 TRIM_RAM_CTL — RAM trim control for less than 100MHz SRAMs
  [31:0] TRIM
0x2108 TRIM_RAM200_CTL — RAM trim control for 100MHz - 200MHz SRAMs
  [31:0] TRIM — See TRIM_RAM_CTL for description. System SRAM memories (SRAM0,1,2) are connected to this register. System SRAM0 uses bias control power switch,so bits [7:5] of this register controls the bias pins of the SRAM0 power switch.
0x210C TRIM_RAM350_CTL — RAM trim control for more than 200MHz SRAMs
  [31:0] TRIM — See TRIM_RAM_CTL for description. CM7 Cache and TCM memories are connected to this register. All CM7 cache and TCM SRAM macros are controlled using bias control power switches, so bits [7:5] of this register controls the bias pins of the CM7 cache and TCM SRAM power switches.
{0x8000+4i} CM0_SYSTEM_INT_CTL[{i}] (i=0..1022) (reset mask 0x80000000) — CM0+ system interrupt control
  [31] CPU_INT_VALID — Interrupt enable: '0': Disabled. The system interrupt will NOT be mapped to any CPU interrupt. '1': Enabled. The system interrupt is mapped on CPU interrupt CPU_INT_IDX. Note: the CPUs have dedicated XXX_SYSTEM_INT_CTL registers. In other words, the CPUs can use different CPU interrupts for the same system interrupt. However, typically only one of the CPUs will have the ENABLED field of a specific system interrupt set to '1'.
  [2:0] CM0_CPU_INT_IDX — CPU interrupt index (legal range [0, 7]). This field specifies to which CPU interrupt the system interrupt is mapped. E.g., if CPU_INT_IDX is '6', the system interrupt is mapped to CPU interrupt '6'. Note: it is possible to map multiple system interrupts to the same CPU interrupt. It is advised to assign different priorities to the CPU interrupts and to assign system interrupts to CPU interrupts accordingly.
{0xA000+4i} CM7_0_SYSTEM_INT_CTL[{i}] (i=0..1022) (reset mask 0x80000000) — CM7 0 system interrupt control
  [31] CPU_INT_VALID — Interrupt enable: '0': Disabled. The system interrupt will NOT be mapped to any CPU interrupt. '1': Enabled. The system interrupt is mapped on CPU interrupt CPU_INT_IDX. Note: the CPUs have dedicated XXX_SYSTEM_INT_CTL registers. In other words, the CPUs can use different CPU interrupts for the same system interrupt. However, typically only one of the CPUs will have the ENABLED field of a specific system interrupt set to '1'.
  [3:0] CPU_INT_IDX — CPU interrupt index (legal range [0, 15]). This field specifies to which CPU interrupt the system interrupt is mapped. E.g., if CPU_INT_IDX is '6', the system interrupt is mapped to CPU interrupt '6'. Note: it is possible to map multiple system interrupts to the same CPU interrupt. It is advised to assign different priorities to the CPU interrupts and to assign system interrupts to CPU interrupts accordingly.
{0xC000+4i} CM7_1_SYSTEM_INT_CTL[{i}] (i=0..1022) (reset mask 0x80000000) — CM7 1 system interrupt control
  [31] CPU_INT_VALID — Refer CM7_0_SYSTEM_INT_CTL description.
  [3:0] CPU_INT_IDX — Refer CM7_0_SYSTEM_INT_CTL description.
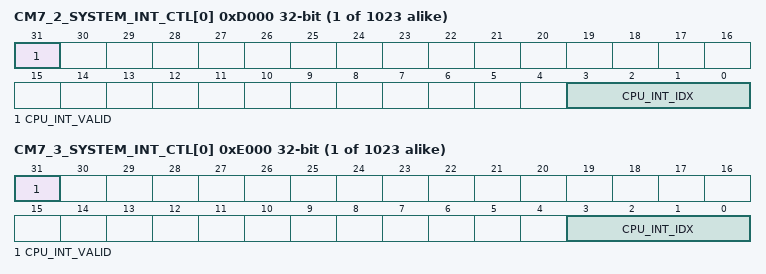
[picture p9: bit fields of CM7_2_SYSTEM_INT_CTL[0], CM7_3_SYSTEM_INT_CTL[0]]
{0xD000+4i} CM7_2_SYSTEM_INT_CTL[{i}] (i=0..1022) (reset mask 0x80000000) — CM7 2 system interrupt control
  [31] CPU_INT_VALID — Refer CM7_2_SYSTEM_INT_CTL description.
  [3:0] CPU_INT_IDX — Refer CM7_2_SYSTEM_INT_CTL description.
{0xE000+4i} CM7_3_SYSTEM_INT_CTL[{i}] (i=0..1022) (reset mask 0x80000000) — CM7 3 system interrupt control
  [31] CPU_INT_VALID — Refer CM7_3_SYSTEM_INT_CTL description.
  [3:0] CPU_INT_IDX — Refer CM7_3_SYSTEM_INT_CTL description.

## Notices in the file
Copyright 2016-2019, Cypress Semiconductor Corporation.  All rights reserved.
You may use this file only in accordance with the license, terms, conditions,
disclaimers, and limitations in the end user license agreement accompanying
the software package with which this file was provided.
